# ESP8266 register map
File version: 1.0
ESP8266 (Xtensa LX106): esp-pacs' SVD with its svdtools patches and binja-espressif's corrections
CPU: Xtensa LX106 1, little endian, no MPU, no FPU, 3 interrupt priority bits
Registers are 32-bit, read-write, reset 0x0 unless marked. A register's access mark holds for its fields unless they carry their own. Offsets are from the block's base; lines under a group give offsets from that group; [hi:lo] are bit positions; {n}, {i} and the like mark numbered series; 'fields as' and 'values as' point back to an identical list; <NAME> marks a mode.

## Memory map
0x3FF00000 DPORT size 0x50
0x3FF00050 EFUSE size 0x10
0x3FF20E44 RNG size 0x4
0x60000000 UART0 size 0x80
0x60000100 SPI1 size 0x100
0x60000200 SPI0 size 0x100
0x60000300 GPIO size 0x74
0x60000600 TIMER size 0x34
0x60000700 RTC size 0x100
0x60000800 IO_MUX size 0x44
0x60000900 WDT size 0x20
0x60000B00 SLC size 0x100
0x60000D00 I2C_ANA size 0x20 — Internal I2C master of the analog blocks (PLL)
0x60000E00 I2S size 0x30
0x60000F00 UART1 size 0x80

## DPORT
Base 0x3FF00000
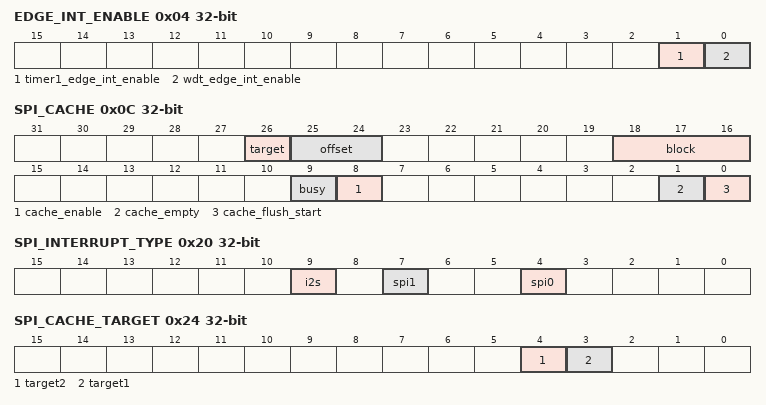
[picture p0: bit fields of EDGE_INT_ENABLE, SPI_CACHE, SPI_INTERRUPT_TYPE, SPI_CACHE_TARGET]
0x04 EDGE_INT_ENABLE access not given
  [1] timer1_edge_int_enable — Enable the timer1 edge interrupt
  [0] wdt_edge_int_enable — Enable the watchdog timer edge interrupt
0x0C SPI_CACHE — Controls SPI memory-mapped caching
  [26] target — Controls where the spi flash is mapped (unconfirmed)
  [25:24] offset — Offset within block to map, in megabytes
  [18:16] block — Flash memory block to map, in 2mb blocks
  [9] busy — SPI busy
  [8] cache_enable
  [1] cache_empty — Cache is empty
  [0] cache_flush_start — Flush cache
0x14 DPORT_CTL
  [0] DPORT_CTL_DOUBLE_CLK
0x20 SPI_INTERRUPT_TYPE ro
  [9] i2s — I2S interrupt
  [7] spi1 — SPI1 interrupt
  [4] spi0 — SPI0 interrupt
0x24 SPI_CACHE_TARGET — Control where the cache is mapped (unconfirmed)
  [4] target2, [3] target1
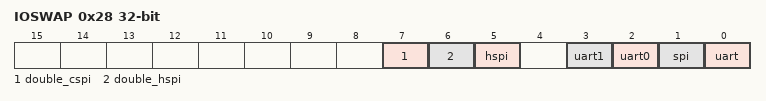
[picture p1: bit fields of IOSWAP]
0x28 IOSWAP
  [7] double_cspi — Set two SPI masters on CSPI
  [6] double_hspi — Set two SPI masters on HSPI
  [5] hspi — Set HSPI with higher priority
  [3] uart1 — Swap UART1 pins (u1rxd <-> u1cts), (u1txd <-> u1rts)
  [2] uart0 — Swap UART0 pins (u0rxd <-> u0cts), (u0txd <-> u0rts)
  [1] spi — Swap SPI
  [0] uart — Swap UART

## EFUSE
Base 0x3FF00050
{0x0+4i} EFUSE_DATA{i} (i=0..3)

## RNG
Base 0x3FF20E44
0x00 rng ro

## GPIO
Base 0x60000300
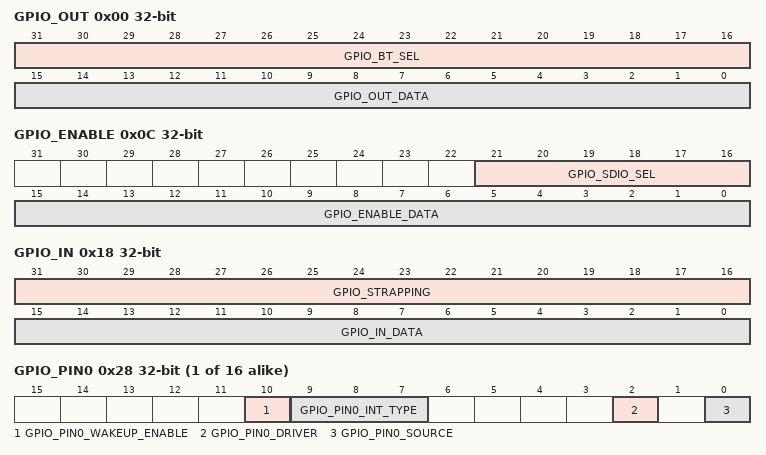
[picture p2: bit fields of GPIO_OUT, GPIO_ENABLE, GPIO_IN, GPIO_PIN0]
0x00 GPIO_OUT — BT-Coexist Selection register
  [31:16] GPIO_BT_SEL — BT-Coexist Selection register
  [15:0] GPIO_OUT_DATA — The output value when the GPIO pin is set as output.
0x04 GPIO_OUT_W1TS wo
  [15:0] GPIO_OUT_DATA_W1TS — Writing 1 into a bit in this register will set the related bit in GPIO_OUT_DATA
0x08 GPIO_OUT_W1TC wo
  [15:0] GPIO_OUT_DATA_W1TC — Writing 1 into a bit in this register will clear the related bit in GPIO_OUT_DATA
0x0C GPIO_ENABLE
  [21:16] GPIO_SDIO_SEL — SDIO-dis selection register
  [15:0] GPIO_ENABLE_DATA — The output enable register.
0x10 GPIO_ENABLE_W1TS wo
  [15:0] GPIO_ENABLE_DATA_W1TS — Writing 1 into a bit in this register will set the related bit in GPIO_ENABLE_DATA
0x14 GPIO_ENABLE_W1TC wo
  [15:0] GPIO_ENABLE_DATA_W1TC — Writing 1 into a bit in this register will clear the related bit in GPIO_ENABLE_DATA
0x18 GPIO_IN — The values of the strapping pins.
  [31:16] GPIO_STRAPPING — The values of the strapping pins.
  [15:0] GPIO_IN_DATA — The values of the GPIO pins when the GPIO pin is set as input.
0x1C GPIO_STATUS
  [15:0] GPIO_STATUS_INTERRUPT — Interrupt enable register.
0x20 GPIO_STATUS_W1TS wo
  [15:0] GPIO_STATUS_INTERRUPT_W1TS — Writing 1 into a bit in this register will set the related bit in GPIO_STATUS_INTERRUPT
0x24 GPIO_STATUS_W1TC wo
  [15:0] GPIO_STATUS_INTERRUPT_W1TC — Writing 1 into a bit in this register will clear the related bit in GPIO_STATUS_INTERRUPT
{0x28+4i} GPIO_PIN{i} (i=0..15)
  [10] GPIO_PIN{i}_WAKEUP_ENABLE — 0: disable; 1: enable GPIO wakeup CPU, only when GPIO_PIN0_INT_TYPE is 0x4 or 0x5
  [9:7] GPIO_PIN{i}_INT_TYPE — 0: disable; 1: positive edge; 2: negative edge; 3: both types of edge; 4: low-level; 5: high-level
    0=disabled (interrupt is disabled); 1=positive_edge (interrupt is triggered on the positive edge); 2=negative_edge (interrupt is triggered on the negative edge); 3=both_edges (interrupt is triggered on both edges); 4=low_level (interrupt is triggered on the low level); 5=high_level (interrupt is triggered on the high level)
  [2] GPIO_PIN{i}_DRIVER — 1: open drain; 0: normal
    0=normal; 1=open_drain
  [0] GPIO_PIN{i}_SOURCE — 1: sigma-delta; 0: GPIO_DATA
    0=gpio_data; 1=sigma_delta
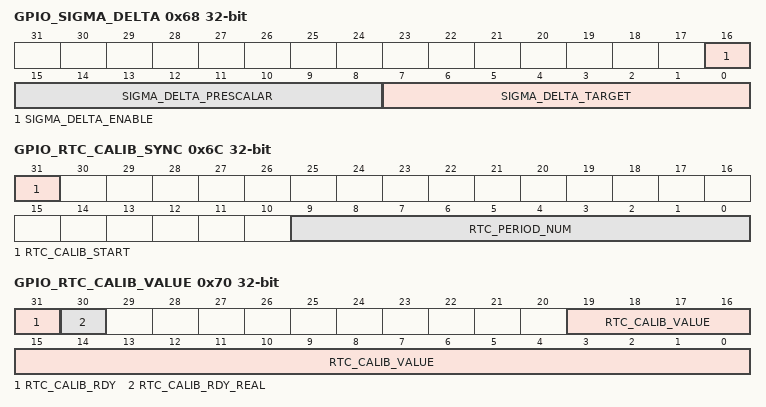
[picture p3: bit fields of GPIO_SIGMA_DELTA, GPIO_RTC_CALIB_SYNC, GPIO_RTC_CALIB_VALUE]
0x68 GPIO_SIGMA_DELTA
  [16] SIGMA_DELTA_ENABLE — 1: enable sigma-delta; 0: disable
  [15:8] SIGMA_DELTA_PRESCALAR — Clock pre-divider for sigma-delta.
  [7:0] SIGMA_DELTA_TARGET — target level of the sigma-delta. It is a signed byte.
0x6C GPIO_RTC_CALIB_SYNC — Positvie edge of this bit will trigger the RTC-clock-calibration process.
  [31] RTC_CALIB_START — Positvie edge of this bit will trigger the RTC-clock-calibration process.
  [9:0] RTC_PERIOD_NUM — The cycle number of RTC-clock during RTC-clock-calibration
0x70 GPIO_RTC_CALIB_VALUE — 0: during RTC-clock-calibration; 1: RTC-clock-calibration is done
  [31] RTC_CALIB_RDY — 0: during RTC-clock-calibration; 1: RTC-clock-calibration is done
  [30] RTC_CALIB_RDY_REAL — 0: during RTC-clock-calibration; 1: RTC-clock-calibration is done
  [19:0] RTC_CALIB_VALUE — The cycle number of clk_xtal (crystal clock) for the RTC_PERIOD_NUM cycles of RTC-clock

## Licence text in the file
Generated with svdtools from the ESP8266 SVD file and patches of esp-rs/esp-pacs (commit c01397fbba0bbf01c49918e050e71eed9bbdd2d5, esp8266/svd/), Copyright The esp-rs Project Developers, licensed under the MIT License or the Apache License, Version 2.0, at your option. esp-pacs generated its file from the register headers of Espressif's ESP8266 SDK (Apache-2.0). binja-espressif's changes (view/espressif/svd/esp8266.yaml) are licensed under the MIT License.
